# ADuCM350 register map
Vendor: Analog Devices; Series: ARMCM3; File version: 0.1
CPU: CM3 r2p1, little endian, no MPU, no FPU, 3 interrupt priority bits
Registers are 16-bit, access not given, no defined reset value unless marked. A register's access mark holds for its fields unless they carry their own. Offsets are from the block's base; [hi:lo] are bit positions; {n}, {i} and the like mark numbered series.

## DMA
Base 0x40010000
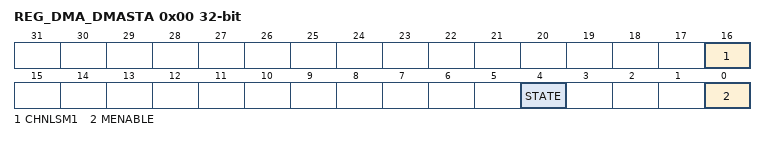
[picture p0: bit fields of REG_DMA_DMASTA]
0x00 REG_DMA_DMASTA 32-bit — DMA DMA Status
  [16] CHNLSM1 — Number of available DMA channels minus 1
  [4] STATE — Current state of DMA controller
  [0] MENABLE — Enable status of the controller
0x04 REG_DMA_DMACFG 32-bit — DMA DMA Configuration
  [0] MENABLE — Controller enable
0x08 REG_DMA_DMAPDBPTR — DMA DMA channel primary control data base pointer
  [15:0] VALUE
0x0C REG_DMA_DMAADBPTR — DMA DMA channel alternate control data base pointer
  [15:0] VALUE
0x14 REG_DMA_DMASWREQ — DMA DMA channel software request
  [0] CHSWREQ — Generate software request
0x20 REG_DMA_DMARMSKSET — DMA DMA channel request mask set
  [0] CHREQMSET — Mask requests from DMA channels
0x24 REG_DMA_DMARMSKCLR — DMA DMA channel request mask clear
  [0] CHREQMCLR — Clear REQ_MASK_SET bits in DMARMSKSET
0x28 REG_DMA_DMAENSET — DMA DMA channel enable set
  [0] CHENSET — Enable DMA channels
0x2C REG_DMA_DMAENCLR — DMA DMA channel enable clear
  [0] CHENCLR — Disable DMA channels
0x30 REG_DMA_DMAALTSET — DMA DMA channel primary-alternate set
  [0] CHPRIALTSET — Control struct status / select alt struct
0x34 REG_DMA_DMAALTCLR — DMA DMA channel primary-alternate clear
  [0] CHPRIALTCLR — Select primary data struct
0x38 REG_DMA_DMAPRISET — DMA DMA channel priority set
  [0] CHPRISET — Configure channel for high priority
0x3C REG_DMA_DMAPRICLR — DMA DMA channel priority clear
  [0] CHPRICLR — Configure channel for default priority level
0x48 REG_DMA_DMAERRCHNLCLR — DMA DMA Per Channel Error Clear
  [0] CHNL — Per channel Bus error status/ Per channel bus error clear
0x4C REG_DMA_DMAERRCLR — DMA DMA bus error clear
  [0] ERRCLR — Bus error status
0x50 REG_DMA_DMAINVALIDDESCCLR — DMA DMA Per Channel Invalid Descriptor Clear
  [0] CHNL — Per channel Invalid Descriptor status/ Per channel Invalid descriptor status clear
0x800 REG_DMA_DMABSSET — DMA DMA channel bytes swap enable set
  [0] CHBSWAPSET — Byte swap status
0x804 REG_DMA_DMABSCLR — DMA DMA channel bytes swap enable clear
  [0] CHBSWAPCLR — Disable byte swap
0x810 REG_DMA_DMASRCADSSET — DMA DMA channel source address decrement enable set
  [0] CHSRCADRDECSET — Source Address decrement status / configure Source address decrement
0x814 REG_DMA_DMASRCADCLR — DMA DMA channel source address decrement enable clear
  [0] CHADRDECCLR — Disable source address decrement
0x818 REG_DMA_DMADSTADSET — DMA DMA channel destination address decrement enable set
  [0] CHDSTADRDECSET — Destination Address decrement status / configure destination address decrement
0x81C REG_DMA_DMADSTADCLR — DMA DMA channel destination address decrement enable clear
  [0] CHADRDECCLR — Disable destination address decrement
0xFE0 REG_DMA_DMAREVID — DMA DMA Controller Revision ID
  [0] DMAREVID — DMA Controller revision ID

## FEE0 — Instruction Flash Controller
Base 0x40018000
0x00 REG_FEE0_FEESTA — FEE0 Status
  [15:0] VALUE
0x04 REG_FEE0_FEECON0 — FEE0 Command Control
  [15:0] VALUE
0x08 REG_FEE0_FEECMD — FEE0 Command
  [15:0] VALUE
0x10 REG_FEE0_FEEADR0L — FEE0 Lower page address
  [15:0] VALUE
0x14 REG_FEE0_FEEADR0H — FEE0 Upper page address
  [15:0] VALUE
0x18 REG_FEE0_FEEADR1L — FEE0 Lower page address
  [15:0] VALUE
0x1C REG_FEE0_FEEADR1H — FEE0 Upper page address
  [15:0] VALUE
0x20 REG_FEE0_FEEKEY — FEE0 Key
  [15:0] VALUE
0x30 REG_FEE0_FEESIGL — FEE0 Lower halfword of signature
  [15:0] VALUE
0x34 REG_FEE0_FEESIGH — FEE0 Upper halfword of signature
  [15:0] VALUE
0x48 REG_FEE0_FEEADRAL — FEE0 Lower halfword of write abort address
  [15:0] VALUE
0x4C REG_FEE0_FEEADRAH — FEE0 Upper halfword of write abort address
  [15:0] VALUE
0x50 REG_FEE0_FEEPARCTL — FEE0 Parity Control Register
  [15:0] VALUE
0x54 REG_FEE0_FEEPARSTA — FEE0 Parity Status Register
  [15:0] VALUE
0x58 REG_FEE0_FEEPARADRL — FEE0 Parity Error Address Low
  [15:0] VALUE
0x5C REG_FEE0_FEEPARADRH — FEE0 Parity Error Address High
  [15:0] VALUE
{0x78+4i} REG_FEE0_FEEAEN{i} (i=0..2) — FEE0 System IRQ abort enable for interrupts {16i+15} to {16i}
  [15:0] VALUE
0x84 REG_FEE0_FEEAEN3 — FEE0 System IRQ abort enable for interrupts 60 to 48
  [15:0] VALUE

## GPF — General Purpose Flash Controller
Base 0x4001C000
0x00 REG_GPF_GPFEESTA — GPF Status
  [15:0] VALUE
0x04 REG_GPF_GPFEECON0 — GPF Command Control
  [15:0] VALUE
0x08 REG_GPF_GPFEECMD — GPF Command
  [15:0] VALUE
0x10 REG_GPF_GPFEEADR0L — GPF Lower page address
  [15:0] VALUE
0x18 REG_GPF_GPFEEADR1L — GPF Lower page address
  [15:0] VALUE
0x20 REG_GPF_GPFEEKEY — GPF Key
  [15:0] VALUE
0x30 REG_GPF_GPFEESIGL — GPF Lower halfword of signature
  [15:0] VALUE
0x34 REG_GPF_GPFEESIGH — GPF Upper halfword of signature
  [15:0] VALUE
0x48 REG_GPF_GPFEEADRAL — GPF Lower halfword of write abort address
  [15:0] VALUE
0x4C REG_GPF_GPFEEADRAH — GPF Upper halfword of write abort address
  [15:0] VALUE
{0x78+4i} REG_GPF_GPFEEAEN{i} (i=0..2) — GPF System IRQ abort enable for interrupts {16i+15} to {16i}
  [15:0] VALUE
0x84 REG_GPF_GPFEEAEN3 — GPF System IRQ abort enable for interrupts 60 to 48
  [15:0] VALUE

## GPIO0 — GPIO
Base 0x40020000
0x00 REG_GPIO0_GPCON — GPIO0 GPIO Port 0 Configuration
  [15:0] VALUE
0x04 REG_GPIO0_GPOEN — GPIO0 GPIO Port 0 output enable
  [15:0] VALUE
0x08 REG_GPIO0_GPPE — GPIO0 GPIO Port 0 output pullup/pulldown enable
  [15:0] VALUE
0x0C REG_GPIO0_GPIEN — GPIO0 GPIO Port 0 Input Path Enable
  [15:0] VALUE
0x10 REG_GPIO0_GPIN — GPIO0 GPIO Port 0 registered data input
  [15:0] VALUE
0x14 REG_GPIO0_GPOUT — GPIO0 GPIO Port 0 data output
  [15:0] VALUE
0x18 REG_GPIO0_GPSET — GPIO0 GPIO Port 0 data out set
  [15:0] VALUE
0x1C REG_GPIO0_GPCLR — GPIO0 GPIO Port 0 data out clear
  [15:0] VALUE
0x20 REG_GPIO0_GPTGL — GPIO0 GPIO Port 0 pin toggle
  [15:0] VALUE
0x24 REG_GPIO0_GPPOL — GPIO0 GPIO Port 0 interrupt polarity
  [15:0] VALUE
0x28 REG_GPIO0_GPIENA — GPIO0 GPIO Port 0 interrupt A enable
  [15:0] VALUE
0x2C REG_GPIO0_GPIENB — GPIO0 GPIO Port 0 interrupt B enable
  [15:0] VALUE
0x30 REG_GPIO0_GPINT — GPIO0 GPIO Port 0 interrupt Status
  [15:0] VALUE

## SPIH — SPIH Master/Slave
Base 0x40024000
0x00 REG_SPIH_SPIH0STA — SPIH Status
  [15:0] VALUE
0x04 REG_SPIH_SPIH0RX — SPIH Receive
  [15:0] VALUE
0x08 REG_SPIH_SPIH0TX — SPIH Transmit
  [15:0] VALUE
0x0C REG_SPIH_SPIH0DIV — SPIH Baud rate selection
  [15:0] VALUE
0x10 REG_SPIH_SPIH0CON — SPIH SPI configuration
  [15:0] VALUE
0x14 REG_SPIH_SPIH0DMA — SPIH SPI DMA enable
  [15:0] VALUE
0x18 REG_SPIH_SPIH0CNT — SPIH Transfer byte count
  [15:0] VALUE

## CRC — CRC Engine
Base 0x4002C000
0x00 REG_CRC_CRC_CTL — CRC CRC Control Register
  [15:0] VALUE
0x04 REG_CRC_CRC_IPDATA — CRC Input Data Register
  [15:0] VALUE
0x08 REG_CRC_CRC_RESULT — CRC CRC Result Register
  [15:0] VALUE

## PDI — Parallel Display Interface
Base 0x40030000
0x00 REG_PDI_PDI_CFG — PDI PDI Configuration Register
  [15:0] VALUE
0x04 REG_PDI_PDI_INT_SET — PDI PDI Interrupt Set Register
  [15:0] VALUE
0x08 REG_PDI_PDI_INT_CLR — PDI PDI Interrupt Clear Register
  [15:0] VALUE
0x0C REG_PDI_PDI_STAT — PDI PDI Status Register
  [15:0] VALUE
0x10 REG_PDI_PDI_CMD — PDI PDI Command Register
  [15:0] VALUE
0x14 REG_PDI_PDI_FRDATA_N — PDI PDI Frame Data Count Register
  [15:0] VALUE
0x18 REG_PDI_PDI_FIFO — PDI PDI Parameter FIFO
  [15:0] VALUE
0x1C REG_PDI_PDI_IF_TIMING — PDI PDI Interface Timing Register
  [15:0] VALUE
